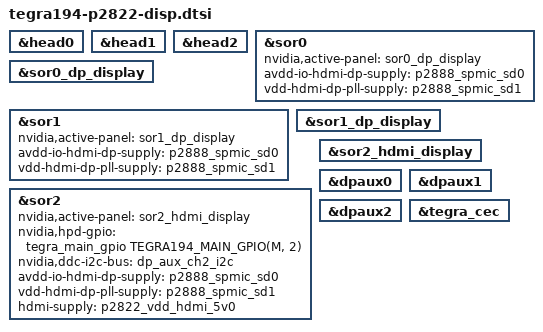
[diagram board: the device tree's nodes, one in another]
/*
 * Copyright (c) 2017-2020, NVIDIA CORPORATION.  All rights reserved.
 *
 * This program is free software; you can redistribute it and/or modify it
 * under the terms and conditions of the GNU General Public License,
 * version 2, as published by the Free Software Foundation.
 *
 * This program is distributed in the hope it will be useful, but WITHOUT
 * ANY WARRANTY; without even the implied warranty of MERCHANTABILITY or
 * FITNESS FOR A PARTICULAR PURPOSE.  See the GNU General Public License for
 * more details.
 *
 * You should have received a copy of the GNU General Public License
 * along with this program.  If not, see <http://www.gnu.org/licenses/>.
 */

/*
 * tegra194-p2822-disp.dtsi:
 */

#include "tegra194-fixed-regulator-p2822-1000.dtsi"
#include "tegra194-spmic-p2888-0001.dtsi"

&head0 {
	status = "okay";
};

&head1 {
	status = "okay";
};

&head2 {
	status = "okay";
};


&sor0 {
	status = "okay";
	nvidia,active-panel = <&sor0_dp_display>;
	avdd-io-hdmi-dp-supply = <&p2888_spmic_sd0>;
	vdd-hdmi-dp-pll-supply = <&p2888_spmic_sd1>;
};

&sor0_dp_display {
	status = "okay";
};

&sor1 {
	status = "okay";
	nvidia,active-panel = <&sor1_dp_display>;
	avdd-io-hdmi-dp-supply = <&p2888_spmic_sd0>;
	vdd-hdmi-dp-pll-supply = <&p2888_spmic_sd1>;
};

&sor1_dp_display {
	status = "okay";
};

&sor2 {
	status = "okay";
	nvidia,active-panel = <&sor2_hdmi_display>;
	nvidia,hpd-gpio = <&tegra_main_gpio TEGRA194_MAIN_GPIO(M, 2) GPIO_ACTIVE_HIGH>;
	nvidia,ddc-i2c-bus = <&dp_aux_ch2_i2c>;
	avdd-io-hdmi-dp-supply = <&p2888_spmic_sd0>; /* 1v0 */
	vdd-hdmi-dp-pll-supply = <&p2888_spmic_sd1>; /* 1v8 */
	hdmi-supply = <&p2822_vdd_hdmi_5v0>; /* 5v0 */
};

&sor2_hdmi_display {
	status = "okay";
};

&dpaux0 {
	status = "okay";
};

&dpaux1 {
	status = "okay";
};

&dpaux2 {
	status = "okay";
};

&tegra_cec {
	status = "okay";
};
